# STM32L562 register map
File version: 1.1
Registers are 32-bit, read-write, reset 0x0 unless marked. A register's access mark holds for its fields unless they carry their own. Offsets are from the block's base; lines under a group give offsets from that group; [hi:lo] are bit positions; {n}, {i} and the like mark numbered series; 'fields as' and 'values as' point back to an identical list; <NAME> marks a mode.

## Memory map
0x4002F400 EXTI size 0x400 — External interrupt/event controller

## Interrupts
1 PVD_PVM (EXTI) — PVD/PVM1/PVM2/PVM3/PVM4 through EXTI
4 TAMP (EXTI) — TAMPTamper global interrupt (EXTI line 19)
5 TAMP_S (EXTI) — Tamper secure global interrupt (EXTI line 20)
{n+11} EXTI{n} (EXTI) (n=0..15) — EXTI line{n} interrupt

## EXTI — External interrupt/event controller
Base 0x4002F400
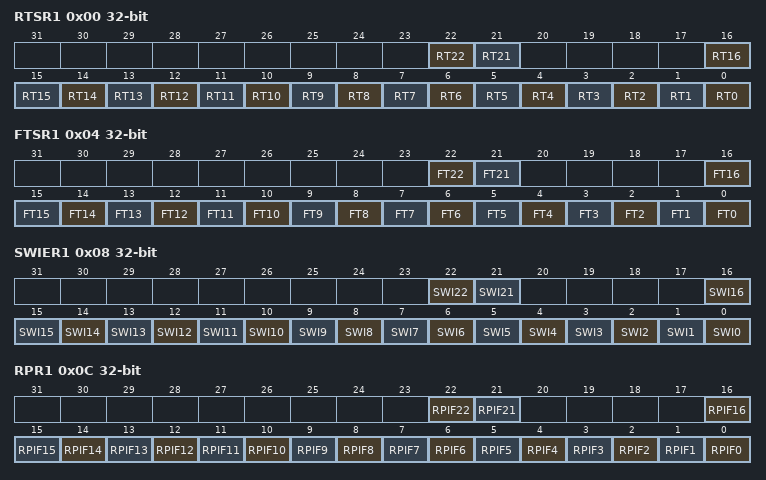
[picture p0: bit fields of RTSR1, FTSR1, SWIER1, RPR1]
0x00 RTSR1 — EXTI rising trigger selection register
  [22] RT22 — Rising trigger event configuration bit of configurable event input x
  [21] RT21 — Rising trigger event configuration bit of configurable event input x
  [n] RT{n} (n=0..16) — Rising trigger event configuration bit of configurable event input x
0x04 FTSR1 — EXTI falling trigger selection register
  [22] FT22 — Falling trigger event configuration bit of configurable event input x
  [21] FT21 — Falling trigger event configuration bit of configurable event input x
  [n] FT{n} (n=0..16) — Falling trigger event configuration bit of configurable event input x
0x08 SWIER1 — EXTI software interrupt event register
  [22] SWI22 — Software interrupt on event x
  [21] SWI21 — Software interrupt on event x
  [n] SWI{n} (n=0..16) — Software interrupt on event x
0x0C RPR1 — EXTI rising edge pending register
  [22] RPIF22 — configurable event inputs x rising edge pending bit
  [21] RPIF21 — configurable event inputs x rising edge pending bit
  [n] RPIF{n} (n=0..16) — configurable event inputs x rising edge pending bit
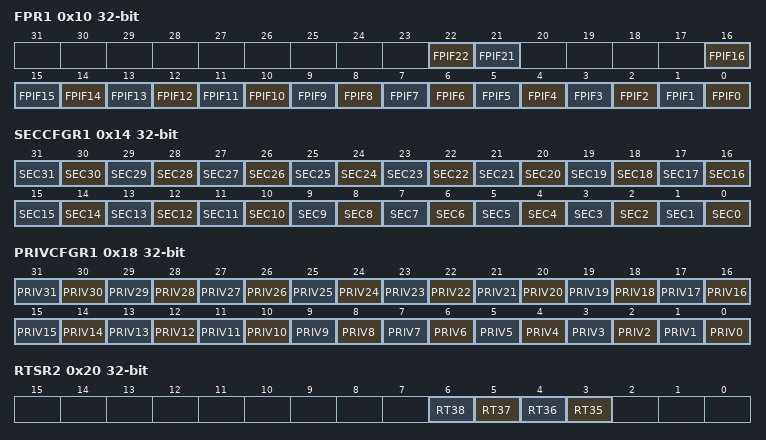
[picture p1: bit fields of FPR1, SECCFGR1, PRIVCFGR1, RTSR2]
0x10 FPR1 — EXTI falling edge pending register
  [22] FPIF22 — configurable event inputs x falling edge pending bit.
  [21] FPIF21 — configurable event inputs x falling edge pending bit.
  [n] FPIF{n} (n=0..16) — configurable event inputs x falling edge pending bit.
0x14 SECCFGR1 — EXTI security configuration register
  [n] SEC{n} (n=0..31) — Security enable on event input x
0x18 PRIVCFGR1 — EXTI privilege configuration register
  [n] PRIV{n} (n=0..31) — Security enable on event input x
0x20 RTSR2 — EXTI rising trigger selection register
  [n-32] RT{n} (n=35..38) — Rising trigger event configuration bit of configurable event input x
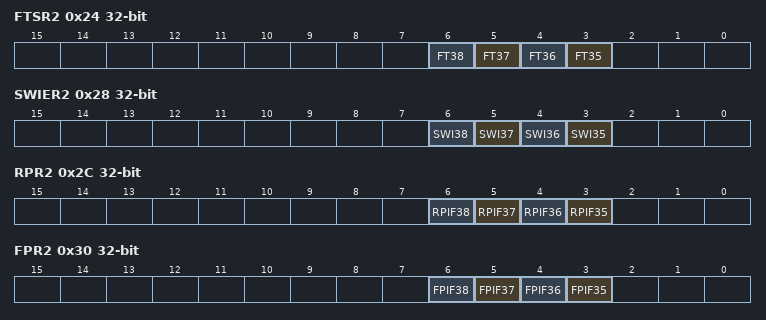
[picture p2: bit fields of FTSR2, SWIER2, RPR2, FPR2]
0x24 FTSR2 — EXTI falling trigger selection register
  [n-32] FT{n} (n=35..38)
0x28 SWIER2 — EXTI software interrupt event register
  [n-32] SWI{n} (n=35..38)
0x2C RPR2 — EXTI rising edge pending register
  [n-32] RPIF{n} (n=35..38)
0x30 FPR2 — EXTI falling edge pending register
  [n-32] FPIF{n} (n=35..38)
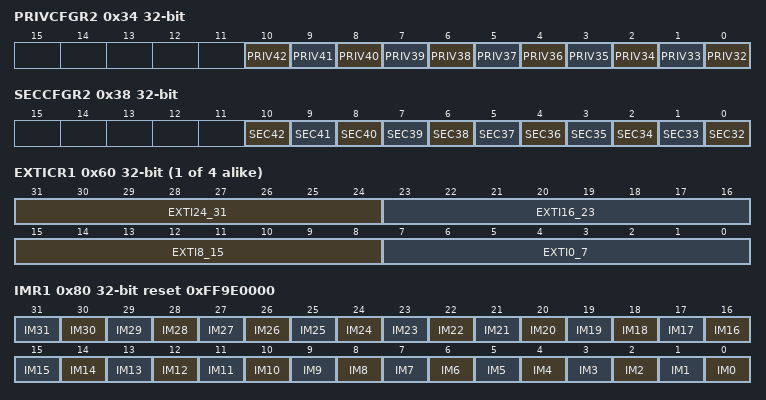
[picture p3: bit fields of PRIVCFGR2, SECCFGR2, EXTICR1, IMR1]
0x34 PRIVCFGR2 — EXTI security enable register
  [n-32] PRIV{n} (n=32..42)
0x38 SECCFGR2 — EXTI security enable register
  [n-32] SEC{n} (n=32..42)
{0x5C+4i} EXTICR{i} (i=1..4) — EXTI external interrupt selection register
  [31:24] EXTI24_31 — EXTIm+3 GPIO port selection
  [23:16] EXTI16_23 — EXTIm+2 GPIO port selection
  [15:8] EXTI8_15 — EXTIm+1 GPIO port selection
  [7:0] EXTI0_7 — EXTIm GPIO port selection
0x70 LOCKRG — EXTI lock register
  [0] LOCK
0x80 IMR1 reset 0xFF9E0000 — EXTI CPU wakeup with interrupt mask register
  [n] IM{n} (n=0..31) — CPU wakeup with interrupt mask on event input
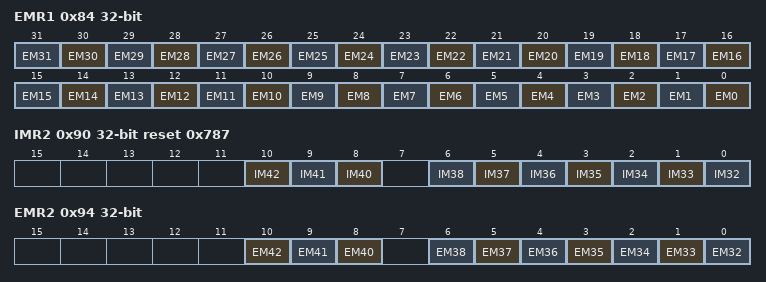
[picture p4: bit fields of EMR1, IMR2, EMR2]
0x84 EMR1 — EXTI CPU wakeup with event mask register
  [n] EM{n} (n=0..31) — CPU wakeup with interrupt mask on event input
0x90 IMR2 reset 0x787 — EXTI CPUm wakeup with interrupt mask register
  [10] IM42 — CPU wakeup with interrupt mask on event input
  [9] IM41 — CPU wakeup with interrupt mask on event input
  [8] IM40 — CPU wakeup with interrupt mask on event input
  [n-32] IM{n} (n=32..38) — CPU wakeup with interrupt mask on event input
0x94 EMR2 — EXTI CPU wakeup with event mask register
  [10] EM42 — CPU wakeup with interrupt mask on event input
  [9] EM41 — CPU wakeup with interrupt mask on event input
  [8] EM40 — CPU wakeup with interrupt mask on event input
  [n-32] EM{n} (n=32..38) — CPU wakeup with interrupt mask on event input
